AUTOSAR XML (schema 4-0-3)
package /ComponentTypes
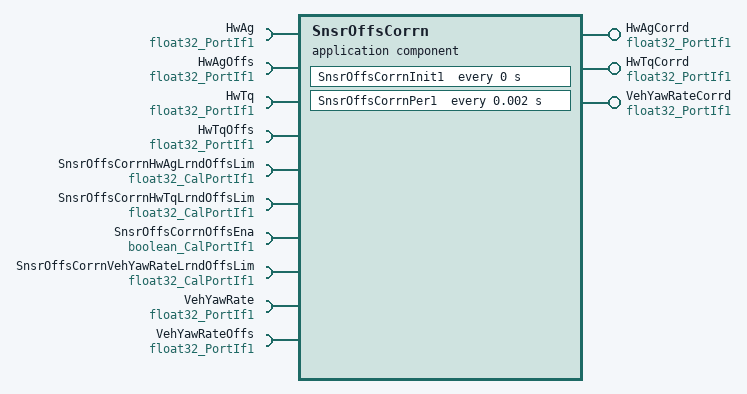
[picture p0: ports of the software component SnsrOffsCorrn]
  application sw component type SnsrOffsCorrn
    provide port HwAgCorrd: nonqueued-sender-com-spec{data-element=Val, init-value=0}, provided-interface=float32_PortIf1
    provide port HwTqCorrd: nonqueued-sender-com-spec{data-element=Val, init-value=0}, provided-interface=float32_PortIf1
    provide port VehYawRateCorrd: nonqueued-sender-com-spec{data-element=Val, init-value=0}, provided-interface=float32_PortIf1
    10 x require port:
      HwAg: nonqueued-receiver-com-spec{data-element=Val, filter=data-filter-type=ALWAYS, init-value=0}, required-interface=float32_PortIf1
      HwAgOffs: nonqueued-receiver-com-spec{data-element=Val, filter=data-filter-type=ALWAYS, init-value=0}, required-interface=float32_PortIf1
      HwTq: nonqueued-receiver-com-spec{data-element=Val, filter=data-filter-type=ALWAYS, init-value=0}, required-interface=float32_PortIf1
      HwTqOffs: nonqueued-receiver-com-spec{data-element=Val, filter=data-filter-type=ALWAYS, init-value=0}, required-interface=float32_PortIf1
      SnsrOffsCorrnHwAgLrndOffsLim: parameter-require-com-spec{init-value=5, parameter=Val}, required-interface=float32_CalPortIf1
      SnsrOffsCorrnHwTqLrndOffsLim: parameter-require-com-spec{init-value=0.5, parameter=Val}, required-interface=float32_CalPortIf1
      SnsrOffsCorrnOffsEna: parameter-require-com-spec{init-value=0, parameter=Logl}, required-interface=boolean_CalPortIf1
      SnsrOffsCorrnVehYawRateLrndOffsLim: parameter-require-com-spec{init-value=5, parameter=Val}, required-interface=float32_CalPortIf1
      VehYawRate: nonqueued-receiver-com-spec{data-element=Val, filter=data-filter-type=ALWAYS, init-value=0}, required-interface=float32_PortIf1
      VehYawRateOffs: nonqueued-receiver-com-spec{data-element=Val, filter=data-filter-type=ALWAYS, init-value=0}, required-interface=float32_PortIf1
    behavior SnsrOffsCorrn_InternalBehavior
      timing event SnsrOffsCorrn_InitEvent: start-on-event=SnsrOffsCorrnInit1, period=0
      timing event TMT_SnsrOffsCorrnPer1: start-on-event=SnsrOffsCorrnPer1, period=0.002
      runnable SnsrOffsCorrnInit1
      runnable SnsrOffsCorrnPer1
        data-receive-point-by-arguments:
          6 x access:
            REC_HwAg_Val: accessed-variable=HwAg.Val
            REC_HwAgOffs_Val: accessed-variable=HwAgOffs.Val
            REC_HwTq_Val: accessed-variable=HwTq.Val
            REC_HwTqOffs_Val: accessed-variable=HwTqOffs.Val
            REC_VehYawRate_Val: accessed-variable=VehYawRate.Val
            REC_VehYawRateOffs_Val: accessed-variable=VehYawRateOffs.Val
        data-send-points:
          access SEND_HwAgCorrd_Val: accessed-variable=HwAgCorrd.Val
          access SEND_HwTqCorrd_Val: accessed-variable=HwTqCorrd.Val
          access SEND_VehYawRateCorrd_Val: accessed-variable=VehYawRateCorrd.Val
  swc implementation SnsrOffsCorrn_Implementation: behavior=SnsrOffsCorrn_InternalBehavior
    code-descriptors:
      code Default: artifact-descriptors=autosar-engineering-object={short-label=Default, category=SWSRC}
